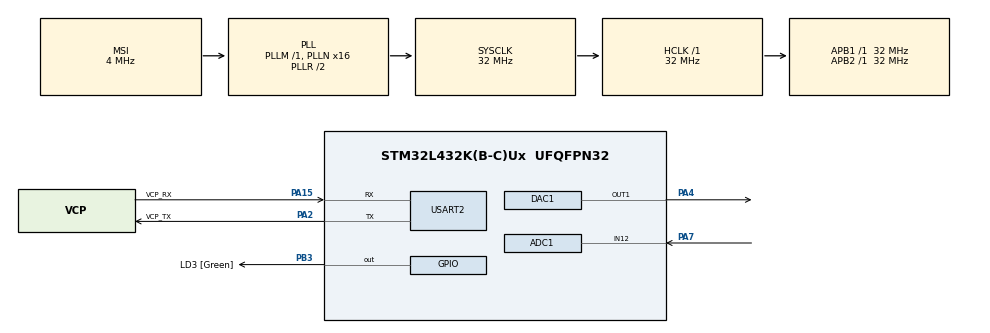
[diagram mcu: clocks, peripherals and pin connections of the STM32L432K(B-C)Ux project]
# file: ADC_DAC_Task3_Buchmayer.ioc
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ADC1.Channel-0\#ChannelRegularConversion=ADC_CHANNEL_12
ADC1.NbrOfConversionFlag=1
ADC1.OffsetNumber-0\#ChannelRegularConversion=ADC_OFFSET_NONE
ADC1.Rank-0\#ChannelRegularConversion=1
ADC1.SamplingTime-0\#ChannelRegularConversion=ADC_SAMPLETIME_2CYCLES_5
ADC1.master=1
Mcu.Family=STM32L4
Mcu.Name=STM32L432K(B-C)Ux
Mcu.Package=UFQFPN32
NVIC.ADC1_IRQn=true\:0\:0\:false\:false\:true\:true\:true\:true
NVIC.PriorityGroup=NVIC_PRIORITYGROUP_4
PA0.GPIO_Label=MCO [High speed clock in]
PA0.Mode=HSE-External-Clock-Source-for-LittleOrca
PA0.Signal=RCC_CK_IN
PA13\ (JTMS-SWDIO).GPIO_Label=SWDIO
PA13\ (JTMS-SWDIO).Mode=Serial_Wire
PA13\ (JTMS-SWDIO).Signal=SYS_JTMS-SWDIO
PA14\ (JTCK-SWCLK).GPIO_Label=SWCLK
PA14\ (JTCK-SWCLK).Mode=Serial_Wire
PA14\ (JTCK-SWCLK).Signal=SYS_JTCK-SWCLK
PA15\ (JTDI).GPIO_Label=VCP_RX
PA15\ (JTDI).Mode=Asynchronous
PA15\ (JTDI).Signal=USART2_RX
PA2.GPIO_Label=VCP_TX
PA2.Mode=Asynchronous
PA2.Signal=USART2_TX
PA4.Signal=COMP_DAC11_group
PA7.Signal=ADCx_IN12
PB3\ (JTDO-TRACESWO).GPIO_Label=LD3 [Green]
PB3\ (JTDO-TRACESWO).Signal=GPIO_Output
PC14-OSC32_IN\ (PC14).Mode=LSE-External-Oscillator
PC14-OSC32_IN\ (PC14).Signal=RCC_OSC32_IN
PC15-OSC32_OUT\ (PC15).Mode=LSE-External-Oscillator
PC15-OSC32_OUT\ (PC15).Signal=RCC_OSC32_OUT
ProjectManager.HeapSize=0x200
ProjectManager.StackSize=0x400
ProjectManager.TargetToolchain=STM32CubeIDE
RCC.AHBFreq_Value=32000000
RCC.APB1Freq_Value=32000000
RCC.APB1TimFreq_Value=32000000
RCC.APB2Freq_Value=32000000
RCC.APB2TimFreq_Value=32000000
RCC.CortexFreq_Value=32000000
RCC.HCLKFreq_Value=32000000
RCC.HSE_VALUE=8000000
RCC.HSI16_VALUE=16000000
RCC.HSI48_VALUE=48000000
RCC.HSI_VALUE=16000000
RCC.MSI_VALUE=4000000
RCC.PLLMUL=RCC_PLLMUL_4
RCC.PLLN=16
RCC.SYSCLKFreq_VALUE=32000000
RCC.SYSCLKSource=RCC_SYSCLKSOURCE_PLLCLK
RCC.VCOOutputFreq_Value=64000000
SH.ADCx_IN12.0=ADC1_IN12,IN12-Single-Ended
SH.COMP_DAC11_group.0=DAC1_OUT1,DAC_OUT1
TIM6.AutoReloadPreload=TIM_AUTORELOAD_PRELOAD_ENABLE
TIM6.Period=20-1
TIM6.Prescaler=32000-1
USART2.VirtualMode-Asynchronous=VM_ASYNC
VP_TIM6_VS_ClockSourceINT.Mode=Enable_Timer
board=NUCLEO-L432KC

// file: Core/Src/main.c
/* USER CODE BEGIN Header */
/**
  ******************************************************************************
  * @file           : main.c
  * @brief          : Main program body
  ******************************************************************************
  * @attention
  *
  * Copyright (c) 2022 STMicroelectronics.
  * All rights reserved.
  *
  * This software is licensed under terms that can be found in the LICENSE file
  * in the root directory of this software component.
  * If no LICENSE file comes with this software, it is provided AS-IS.
  *
  ******************************************************************************
  */
/* USER CODE END Header */
#include "main.h"

ADC_HandleTypeDef hadc1;

DAC_HandleTypeDef hdac1;

TIM_HandleTypeDef htim6;

UART_HandleTypeDef huart2;

void SystemClock_Config(void);
static void MX_GPIO_Init(void);
static void MX_USART2_UART_Init(void);
static void MX_ADC1_Init(void);
static void MX_DAC1_Init(void);
static void MX_TIM6_Init(void);

/* USER CODE BEGIN 0 */
uint32_t adc_min = 0;
uint32_t adc_max = 4095;
uint32_t led_min = 500; //values: from google and trial and error
uint32_t led_max = 1300;

int map(long x, long in_min, long in_max, long out_min, long out_max){
	return (x - in_min) * (out_max - out_min) / (in_max - in_min) + out_min;
}

//Same code below works for others with the exact same IOC file, but doenst work for me for some reason
//because it for some reason doesnt work on mine i just pasted it into the while loop despite task saying I shouldnt but it works
//void HAL_TIM_PeriodElapsedCallback(TIM_HandleTypeDef *htim) {
//	if(htim == &htim6) {
//		HAL_ADC_Start_IT(&hadc1);
//		uint32_t adc_in = HAL_ADC_GetValue(&hadc1);
//		int led_value = map(adc_in, adc_min, adc_max, led_min, led_max);
//		HAL_DAC_Start(&hdac1, DAC_CHANNEL_1);
//		HAL_DAC_SetValue(&hdac1, DAC_CHANNEL_1, DAC_ALIGN_12B_R, led_value);
//
//	}
//}
//
//void HAL_ADC_ConvCpltCallback(ADC_HandleTypeDef *hadc){
//		HAL_ADC_Start_IT(&hadc1);
//		uint32_t adc_in = HAL_ADC_GetValue(&hadc1);
//		int led_value = map(adc_in, adc_min, adc_max, led_min, led_max);
//		HAL_DAC_Start(&hdac1, DAC_CHANNEL_1);
//		HAL_DAC_SetValue(&hdac1, DAC_CHANNEL_1, DAC_ALIGN_12B_R, led_value);
//
//}

/* USER CODE END 0 */

int main(void)
{

  /* MCU Configuration--------------------------------------------------------*/

  /* Reset of all peripherals, Initializes the Flash interface and the Systick. */
  HAL_Init();

  /* Configure the system clock */
  SystemClock_Config();

  /* Initialize all configured peripherals */
  MX_GPIO_Init();
  MX_USART2_UART_Init();
  MX_ADC1_Init();
  MX_DAC1_Init();
  MX_TIM6_Init();
  /* USER CODE BEGIN 2 */

  HAL_ADC_Start_IT(&hadc1);
  HAL_TIM_Base_Start(&htim6);

  /* USER CODE END 2 */

  /* Infinite loop */
  while (1)
  {

    /* USER CODE BEGIN 3 */
	HAL_ADC_Start_IT(&hadc1);
	uint32_t adc_in = HAL_ADC_GetValue(&hadc1);
	int led_value = map(adc_in, adc_min, adc_max, led_min, led_max);
	HAL_DAC_Start(&hdac1, DAC_CHANNEL_1);
	HAL_DAC_SetValue(&hdac1, DAC_CHANNEL_1, DAC_ALIGN_12B_R, led_value);

  }
  /* USER CODE END 3 */
}

void SystemClock_Config(void)
{
  RCC_OscInitTypeDef RCC_OscInitStruct = {0};
  RCC_ClkInitTypeDef RCC_ClkInitStruct = {0};

  /** Configure the main internal regulator output voltage
  */
  if (HAL_PWREx_ControlVoltageScaling(PWR_REGULATOR_VOLTAGE_SCALE1) != HAL_OK)
  {
    Error_Handler();
  }

  /** Configure LSE Drive Capability
  */
  HAL_PWR_EnableBkUpAccess();
  __HAL_RCC_LSEDRIVE_CONFIG(RCC_LSEDRIVE_LOW);

  /** Initializes the RCC Oscillators according to the specified parameters
  * in the RCC_OscInitTypeDef structure.
  */
  RCC_OscInitStruct.OscillatorType = RCC_OSCILLATORTYPE_LSE|RCC_OSCILLATORTYPE_MSI;
  RCC_OscInitStruct.LSEState = RCC_LSE_ON;
  RCC_OscInitStruct.MSIState = RCC_MSI_ON;
  RCC_OscInitStruct.MSICalibrationValue = 0;
  RCC_OscInitStruct.MSIClockRange = RCC_MSIRANGE_6;
  RCC_OscInitStruct.PLL.PLLState = RCC_PLL_ON;
  RCC_OscInitStruct.PLL.PLLSource = RCC_PLLSOURCE_MSI;
  RCC_OscInitStruct.PLL.PLLM = 1;
  RCC_OscInitStruct.PLL.PLLN = 16;
  RCC_OscInitStruct.PLL.PLLP = RCC_PLLP_DIV7;
  RCC_OscInitStruct.PLL.PLLQ = RCC_PLLQ_DIV2;
  RCC_OscInitStruct.PLL.PLLR = RCC_PLLR_DIV2;
  if (HAL_RCC_OscConfig(&RCC_OscInitStruct) != HAL_OK)
  {
    Error_Handler();
  }

  /** Initializes the CPU, AHB and APB buses clocks
  */
  RCC_ClkInitStruct.ClockType = RCC_CLOCKTYPE_HCLK|RCC_CLOCKTYPE_SYSCLK
                              |RCC_CLOCKTYPE_PCLK1|RCC_CLOCKTYPE_PCLK2;
  RCC_ClkInitStruct.SYSCLKSource = RCC_SYSCLKSOURCE_PLLCLK;
  RCC_ClkInitStruct.AHBCLKDivider = RCC_SYSCLK_DIV1;
  RCC_ClkInitStruct.APB1CLKDivider = RCC_HCLK_DIV1;
  RCC_ClkInitStruct.APB2CLKDivider = RCC_HCLK_DIV1;

  if (HAL_RCC_ClockConfig(&RCC_ClkInitStruct, FLASH_LATENCY_1) != HAL_OK)
  {
    Error_Handler();
  }

  /** Enable MSI Auto calibration
  */
  HAL_RCCEx_EnableMSIPLLMode();
}

static void MX_ADC1_Init(void)
{

  ADC_ChannelConfTypeDef sConfig = {0};

  /** Common config
  */
  hadc1.Instance = ADC1;
  hadc1.Init.ClockPrescaler = ADC_CLOCK_ASYNC_DIV1;
  hadc1.Init.Resolution = ADC_RESOLUTION_12B;
  hadc1.Init.DataAlign = ADC_DATAALIGN_RIGHT;
  hadc1.Init.ScanConvMode = ADC_SCAN_DISABLE;
  hadc1.Init.EOCSelection = ADC_EOC_SINGLE_CONV;
  hadc1.Init.LowPowerAutoWait = DISABLE;
  hadc1.Init.ContinuousConvMode = DISABLE;
  hadc1.Init.NbrOfConversion = 1;
  hadc1.Init.DiscontinuousConvMode = DISABLE;
  hadc1.Init.ExternalTrigConv = ADC_SOFTWARE_START;
  hadc1.Init.ExternalTrigConvEdge = ADC_EXTERNALTRIGCONVEDGE_NONE;
  hadc1.Init.DMAContinuousRequests = DISABLE;
  hadc1.Init.Overrun = ADC_OVR_DATA_PRESERVED;
  hadc1.Init.OversamplingMode = DISABLE;
  if (HAL_ADC_Init(&hadc1) != HAL_OK)
  {
    Error_Handler();
  }

  /** Configure Regular Channel
  */
  sConfig.Channel = ADC_CHANNEL_12;
  sConfig.Rank = ADC_REGULAR_RANK_1;
  sConfig.SamplingTime = ADC_SAMPLETIME_2CYCLES_5;
  sConfig.SingleDiff = ADC_SINGLE_ENDED;
  sConfig.OffsetNumber = ADC_OFFSET_NONE;
  sConfig.Offset = 0;
  if (HAL_ADC_ConfigChannel(&hadc1, &sConfig) != HAL_OK)
  {
    Error_Handler();
  }

}

static void MX_DAC1_Init(void)
{

  DAC_ChannelConfTypeDef sConfig = {0};

  /** DAC Initialization
  */
  hdac1.Instance = DAC1;
  if (HAL_DAC_Init(&hdac1) != HAL_OK)
  {
    Error_Handler();
  }

  /** DAC channel OUT1 config
  */
  sConfig.DAC_SampleAndHold = DAC_SAMPLEANDHOLD_DISABLE;
  sConfig.DAC_Trigger = DAC_TRIGGER_NONE;
  sConfig.DAC_OutputBuffer = DAC_OUTPUTBUFFER_ENABLE;
  sConfig.DAC_ConnectOnChipPeripheral = DAC_CHIPCONNECT_DISABLE;
  sConfig.DAC_UserTrimming = DAC_TRIMMING_FACTORY;
  if (HAL_DAC_ConfigChannel(&hdac1, &sConfig, DAC_CHANNEL_1) != HAL_OK)
  {
    Error_Handler();
  }

}

static void MX_TIM6_Init(void)
{

  TIM_MasterConfigTypeDef sMasterConfig = {0};

  htim6.Instance = TIM6;
  htim6.Init.Prescaler = 32000-1;
  htim6.Init.CounterMode = TIM_COUNTERMODE_UP;
  htim6.Init.Period = 20;
  htim6.Init.AutoReloadPreload = TIM_AUTORELOAD_PRELOAD_ENABLE;
  if (HAL_TIM_Base_Init(&htim6) != HAL_OK)
  {
    Error_Handler();
  }
  sMasterConfig.MasterOutputTrigger = TIM_TRGO_RESET;
  sMasterConfig.MasterSlaveMode = TIM_MASTERSLAVEMODE_DISABLE;
  if (HAL_TIMEx_MasterConfigSynchronization(&htim6, &sMasterConfig) != HAL_OK)
  {
    Error_Handler();
  }

}

static void MX_USART2_UART_Init(void)
{

  huart2.Instance = USART2;
  huart2.Init.BaudRate = 115200;
  huart2.Init.WordLength = UART_WORDLENGTH_8B;
  huart2.Init.StopBits = UART_STOPBITS_1;
  huart2.Init.Parity = UART_PARITY_NONE;
  huart2.Init.Mode = UART_MODE_TX_RX;
  huart2.Init.HwFlowCtl = UART_HWCONTROL_NONE;
  huart2.Init.OverSampling = UART_OVERSAMPLING_16;
  huart2.Init.OneBitSampling = UART_ONE_BIT_SAMPLE_DISABLE;
  huart2.AdvancedInit.AdvFeatureInit = UART_ADVFEATURE_NO_INIT;
  if (HAL_UART_Init(&huart2) != HAL_OK)
  {
    Error_Handler();
  }

}

static void MX_GPIO_Init(void)
{
  GPIO_InitTypeDef GPIO_InitStruct = {0};

  /* GPIO Ports Clock Enable */
  __HAL_RCC_GPIOC_CLK_ENABLE();
  __HAL_RCC_GPIOA_CLK_ENABLE();
  __HAL_RCC_GPIOB_CLK_ENABLE();

  /*Configure GPIO pin Output Level */
  HAL_GPIO_WritePin(LD3_GPIO_Port, LD3_Pin, GPIO_PIN_RESET);

  /*Configure GPIO pin : LD3_Pin */
  GPIO_InitStruct.Pin = LD3_Pin;
  GPIO_InitStruct.Mode = GPIO_MODE_OUTPUT_PP;
  GPIO_InitStruct.Pull = GPIO_NOPULL;
  GPIO_InitStruct.Speed = GPIO_SPEED_FREQ_LOW;
  HAL_GPIO_Init(LD3_GPIO_Port, &GPIO_InitStruct);

}

void Error_Handler(void)
{
  __disable_irq();
  while (1)
  {
  }
}
